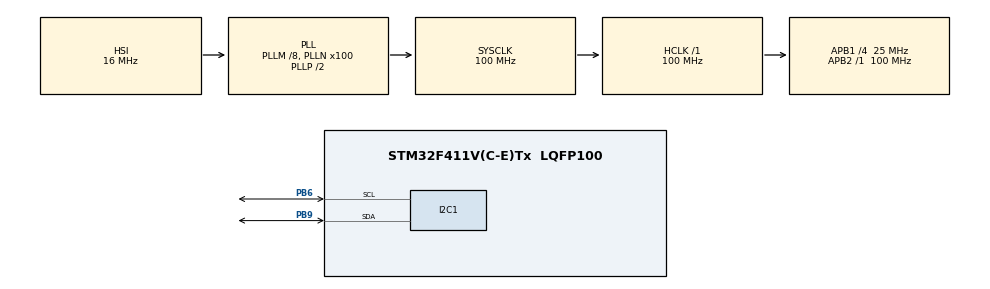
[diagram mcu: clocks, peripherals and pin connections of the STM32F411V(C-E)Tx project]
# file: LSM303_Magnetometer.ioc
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Dma.I2C1_RX.0.Direction=DMA_PERIPH_TO_MEMORY
Dma.I2C1_RX.0.FIFOMode=DMA_FIFOMODE_DISABLE
Dma.I2C1_RX.0.Instance=DMA1_Stream0
Dma.I2C1_RX.0.MemDataAlignment=DMA_MDATAALIGN_BYTE
Dma.I2C1_RX.0.MemInc=DMA_MINC_ENABLE
Dma.I2C1_RX.0.Mode=DMA_CIRCULAR
Dma.I2C1_RX.0.PeriphDataAlignment=DMA_PDATAALIGN_BYTE
Dma.I2C1_RX.0.PeriphInc=DMA_PINC_DISABLE
Dma.I2C1_RX.0.Priority=DMA_PRIORITY_LOW
Dma.I2C1_TX.1.Direction=DMA_MEMORY_TO_PERIPH
Dma.I2C1_TX.1.FIFOMode=DMA_FIFOMODE_DISABLE
Dma.I2C1_TX.1.Instance=DMA1_Stream1
Dma.I2C1_TX.1.MemDataAlignment=DMA_MDATAALIGN_BYTE
Dma.I2C1_TX.1.MemInc=DMA_MINC_ENABLE
Dma.I2C1_TX.1.Mode=DMA_CIRCULAR
Dma.I2C1_TX.1.PeriphDataAlignment=DMA_PDATAALIGN_BYTE
Dma.I2C1_TX.1.PeriphInc=DMA_PINC_DISABLE
Dma.I2C1_TX.1.Priority=DMA_PRIORITY_LOW
Dma.Request0=I2C1_RX
Dma.Request1=I2C1_TX
I2C1.I2C_Mode=I2C_Fast
Mcu.Family=STM32F4
Mcu.Name=STM32F411V(C-E)Tx
Mcu.Package=LQFP100
NVIC.DMA1_Stream0_IRQn=true\:0\:0\:false\:false\:true
NVIC.DMA1_Stream1_IRQn=true\:0\:0\:false\:false\:true
NVIC.PriorityGroup=NVIC_PRIORITYGROUP_4
PB6.Mode=I2C
PB6.Signal=I2C1_SCL
PB9.Mode=I2C
PB9.Signal=I2C1_SDA
ProjectManager.HeapSize=0x200
ProjectManager.StackSize=0x400
ProjectManager.TargetToolchain=SW4STM32
RCC.48MHZClocksFreq_Value=50000000
RCC.AHBFreq_Value=100000000
RCC.APB1CLKDivider=RCC_HCLK_DIV4
RCC.APB1Freq_Value=25000000
RCC.APB1TimFreq_Value=50000000
RCC.APB2Freq_Value=100000000
RCC.APB2TimFreq_Value=100000000
RCC.CortexFreq_Value=100000000
RCC.HCLKFreq_Value=100000000
RCC.HSE_VALUE=25000000
RCC.HSI_VALUE=16000000
RCC.LSE_VALUE=32768
RCC.PLLM=8
RCC.PLLN=100
RCC.SYSCLKFreq_VALUE=100000000
RCC.SYSCLKSource=RCC_SYSCLKSOURCE_PLLCLK
RCC.VCOOutputFreq_Value=200000000
board=LSM303_Magnetometer

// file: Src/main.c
/**
  ******************************************************************************
  * File Name          : main.c
  * Description        : Main program body
  ******************************************************************************
  *
  * COPYRIGHT(c) 2017 STMicroelectronics
  *
  * Redistribution and use in source and binary forms, with or without modification,
  * are permitted provided that the following conditions are met:
  *   1. Redistributions of source code must retain the above copyright notice,
  *      this list of conditions and the following disclaimer.
  *   2. Redistributions in binary form must reproduce the above copyright notice,
  *      this list of conditions and the following disclaimer in the documentation
  *      and/or other materials provided with the distribution.
  *   3. Neither the name of STMicroelectronics nor the names of its contributors
  *      may be used to endorse or promote products derived from this software
  *      without specific prior written permission.
  *
  * THIS SOFTWARE IS PROVIDED BY THE COPYRIGHT HOLDERS AND CONTRIBUTORS "AS IS"
  * AND ANY EXPRESS OR IMPLIED WARRANTIES, INCLUDING, BUT NOT LIMITED TO, THE
  * IMPLIED WARRANTIES OF MERCHANTABILITY AND FITNESS FOR A PARTICULAR PURPOSE ARE
  * DISCLAIMED. IN NO EVENT SHALL THE COPYRIGHT HOLDER OR CONTRIBUTORS BE LIABLE
  * FOR ANY DIRECT, INDIRECT, INCIDENTAL, SPECIAL, EXEMPLARY, OR CONSEQUENTIAL
  * DAMAGES (INCLUDING, BUT NOT LIMITED TO, PROCUREMENT OF SUBSTITUTE GOODS OR
  * SERVICES; LOSS OF USE, DATA, OR PROFITS; OR BUSINESS INTERRUPTION) HOWEVER
  * CAUSED AND ON ANY THEORY OF LIABILITY, WHETHER IN CONTRACT, STRICT LIABILITY,
  * OR TORT (INCLUDING NEGLIGENCE OR OTHERWISE) ARISING IN ANY WAY OUT OF THE USE
  * OF THIS SOFTWARE, EVEN IF ADVISED OF THE POSSIBILITY OF SUCH DAMAGE.
  *
  ******************************************************************************
  */
#include "main.h"
#include "stm32f4xx_hal.h"

/* USER CODE BEGIN Includes */
#include <limits.h>
#include <math.h>
/* USER CODE END Includes */

I2C_HandleTypeDef hi2c1;
DMA_HandleTypeDef hdma_i2c1_rx;
DMA_HandleTypeDef hdma_i2c1_tx;

/* USER CODE BEGIN PV */
/* Private variables ---------------------------------------------------------*/

//MAGNETOMETER ADDRESS
#define LSM303_MAG_ADDRESS (0x1E << 1) //Shift to left because LSB is either 0 or 1, depend on Read or Write operation; HAL drivers set this bit by itself

//CRA_REG_M = [TEMP_EN][0][0][DO2][DO1][DO0][0][0]
#define LSM303_MAG_CRA_REG_M 0x00
#define LSM303_MAG_TEMP_EN 0x80 //Temperature enable
#define LSM303_MAG_0_7_5_HZ 0x00 //DO2-DO0 = 000
#define LSM303_MAG_1_5_HZ 0x04 //DO2-DO0 = 001
#define LSM303_MAG_3_0_HZ 0x08
#define LSM303_MAG_7_5_HZ 0x0C
#define LSM303_MAG_15_HZ 0x10
#define LSM303_MAG_75_HZ 0x18
#define LSM303_MAG_220_HZ 0x1C

//CRB_REG_M = [GN2][GN1][GN0][0][0][0][0][0]
#define LSM303_MAG_CRB_REG_M 0x01
///////////////////////////////////////
#define LSM303_MAG_GAIN_1_3 0x20
#define LSM303_MAG_XY_GAIN_1_3 1100
#define LSM303_MAG_Z_GAIN_1_3 980
///////////////////////////////////////
#define LSM303_MAG_GAIN_1_9 0x40
///////////////////////////////////////
#define LSM303_MAG_GAIN_2_5 0x60
///////////////////////////////////////
#define LSM303_MAG_GAIN_4_0 0x80
///////////////////////////////////////
#define LSM303_MAG_GAIN_4_7 0xA0
///////////////////////////////////////
#define LSM303_MAG_GAIN_5_6 0xC0
///////////////////////////////////////
#define LSM303_MAG_GAIN_8_1 0xD0
#define LSM303_MAG_XY_GAIN_8_1 230
#define LSM303_MAG_Z_GAIN_8_1 205
///////////////////////////////////////

//MR_REG_M = [0][0][0][0][0][0][MD1][MD0]
#define LSM303_MAG_MR_REG_M 0x02
#define LSM303_MAG_CONT_CONV 0x00 //Continuous-conversion mode
#define LSM303_MAG_SINGLE_CONV 0x01
#define LSM303_MAG_SLEEP_MODE1 0x02 //Same as mode2
#define LSM303_MAG_SLEEP_MODE2 0x03 //Same as mode1

//OUT REGISTERS
#define LSM303_MAG_OUT_X_H_M 0x03
#define LSM303_MAG_OUT_X_L_M 0x04
#define LSM303_MAG_OUT_Z_H_M 0x05
#define LSM303_MAG_OUT_Z_L_M 0x06
#define LSM303_MAG_OUT_Y_H_M 0x07
#define LSM303_MAG_OUT_Y_L_M 0x08

#define LSM303_MAG_OUT_XYZ_MULTIREAD (LSM303_MAG_OUT_X_H_M | 0x80)

//SR_REG_M = [--][--][--][--][--][--][LOCK][DRDY]
#define LSM303_MAG_SR_REG_M 0x09
#define LSM303_MAG_LOCK 0x02
#define LSM303_MAG_DATA_READY 0x01

//TEMPERATURE; 12 bits resolution
#define LSM303_MAG_TEMP_OUT_H_M 0x31
#define LSM303_MAG_TEMP_OUT_L_M 0x32
//OTHER SETTINGS
#define LSM303_MAG_RESOLUTION 12

#define LSM303_ACC_XYZ_ENABLE 0x07
#define LSM303_ACC_CTRL_REG1_A 0x20
#define LSM303_ACC_ADDRESS (0x19 << 1)

#define GAUSS_TO_MICROTESLA 100

uint8_t Data[6];
int16_t Axis[3];
float Axis_Gauss[3];
float X_max = 0;
float X_min = 0;

/* USER CODE END PV */

void SystemClock_Config(void);
void Error_Handler(void);
static void MX_GPIO_Init(void);
static void MX_DMA_Init(void);
static void MX_I2C1_Init(void);

/* USER CODE BEGIN PFP */
/* Private function prototypes -----------------------------------------------*/

/* USER CODE END PFP */

int main(void)
{

  /* USER CODE BEGIN 1 */
	uint8_t settings;
  /* USER CODE END 1 */

  /* MCU Configuration----------------------------------------------------------*/

  /* Reset of all peripherals, Initializes the Flash interface and the Systick. */
  HAL_Init();

  /* Configure the system clock */
  SystemClock_Config();

  /* Initialize all configured peripherals */
  MX_GPIO_Init();
  MX_DMA_Init();
  MX_I2C1_Init();

  /* USER CODE BEGIN 2 */
	settings = LSM303_MAG_CONT_CONV;
	HAL_I2C_Mem_Write(&hi2c1, LSM303_MAG_ADDRESS, LSM303_MAG_MR_REG_M, 1, &settings, 1, 100);

	settings = LSM303_MAG_7_5_HZ;
	HAL_I2C_Mem_Write(&hi2c1, LSM303_MAG_ADDRESS, LSM303_MAG_CRA_REG_M, 1, &settings, 1, 100);

	settings = LSM303_MAG_GAIN_1_3;
	HAL_I2C_Mem_Write(&hi2c1, LSM303_MAG_ADDRESS, LSM303_MAG_CRB_REG_M, 1, &settings, 1, 100);

//	settings = LSM303_ACC_XYZ_ENABLE;
//	HAL_I2C_Mem_Write(&hi2c1, LSM303_ACC_ADDRESS, LSM303_ACC_CTRL_REG1_A, 1, &settings, 1, 100);

  /* USER CODE END 2 */

  /* Infinite loop */
  /* USER CODE BEGIN WHILE */
	while (1) {
		HAL_I2C_Mem_Read_DMA(&hi2c1, LSM303_MAG_ADDRESS, LSM303_MAG_OUT_X_H_M, 1, Data, 6);
		Axis[0] = (int16_t)(Data[1] | ((int16_t)Data[0] << 8)); //X
		Axis[1] = (int16_t)(Data[5] | ((int16_t)Data[4] << 8)); //Y
		Axis[2] = (int16_t)(Data[3] | ((int16_t)Data[2] << 8)); //Z

//		temp[0] = ((float)Axis[0] * LSM303_MAG_RESOLUTION) / (float)INT16_MAX;
//		temp[1] = ((float)Axis[1] * LSM303_MAG_RESOLUTION) / (float)INT16_MAX;
//		temp[2] = ((float)Axis[2] * LSM303_MAG_RESOLUTION) / (float)INT16_MAX;

//		Axis_Gauss[0] = (temp[0] / LSM303_MAG_XY_GAIN_1_3)*100;
//		Axis_Gauss[1] = (temp[1] / LSM303_MAG_XY_GAIN_1_3)*100;
//		Axis_Gauss[2] = (temp[2] / LSM303_MAG_Z_GAIN_1_3)*100;

		Axis_Gauss[0] = (float)Axis[0] / LSM303_MAG_XY_GAIN_1_3*GAUSS_TO_MICROTESLA;
		Axis_Gauss[1] = (float)Axis[1] / LSM303_MAG_XY_GAIN_1_3*GAUSS_TO_MICROTESLA;
		Axis_Gauss[2] = (float)Axis[2] / LSM303_MAG_Z_GAIN_1_3*GAUSS_TO_MICROTESLA;

//		if (Axis_Gauss[0] > X_max)
//			X_max = Axis_Gauss[0];
//		else if (Axis_Gauss[0] < X_min)
//			X_min = Axis_Gauss[0];

  /* USER CODE END WHILE */

	}

}

/** System Clock Configuration
*/
void SystemClock_Config(void)
{

  RCC_OscInitTypeDef RCC_OscInitStruct;
  RCC_ClkInitTypeDef RCC_ClkInitStruct;

    /**Configure the main internal regulator output voltage
    */
  __HAL_RCC_PWR_CLK_ENABLE();

  __HAL_PWR_VOLTAGESCALING_CONFIG(PWR_REGULATOR_VOLTAGE_SCALE1);

    /**Initializes the CPU, AHB and APB busses clocks
    */
  RCC_OscInitStruct.OscillatorType = RCC_OSCILLATORTYPE_HSI;
  RCC_OscInitStruct.HSIState = RCC_HSI_ON;
  RCC_OscInitStruct.HSICalibrationValue = 16;
  RCC_OscInitStruct.PLL.PLLState = RCC_PLL_ON;
  RCC_OscInitStruct.PLL.PLLSource = RCC_PLLSOURCE_HSI;
  RCC_OscInitStruct.PLL.PLLM = 8;
  RCC_OscInitStruct.PLL.PLLN = 100;
  RCC_OscInitStruct.PLL.PLLP = RCC_PLLP_DIV2;
  RCC_OscInitStruct.PLL.PLLQ = 4;
  if (HAL_RCC_OscConfig(&RCC_OscInitStruct) != HAL_OK)
  {
    Error_Handler();
  }

    /**Initializes the CPU, AHB and APB busses clocks
    */
  RCC_ClkInitStruct.ClockType = RCC_CLOCKTYPE_HCLK|RCC_CLOCKTYPE_SYSCLK
                              |RCC_CLOCKTYPE_PCLK1|RCC_CLOCKTYPE_PCLK2;
  RCC_ClkInitStruct.SYSCLKSource = RCC_SYSCLKSOURCE_PLLCLK;
  RCC_ClkInitStruct.AHBCLKDivider = RCC_SYSCLK_DIV1;
  RCC_ClkInitStruct.APB1CLKDivider = RCC_HCLK_DIV4;
  RCC_ClkInitStruct.APB2CLKDivider = RCC_HCLK_DIV1;

  if (HAL_RCC_ClockConfig(&RCC_ClkInitStruct, FLASH_LATENCY_3) != HAL_OK)
  {
    Error_Handler();
  }

    /**Configure the Systick interrupt time
    */
  HAL_SYSTICK_Config(HAL_RCC_GetHCLKFreq()/1000);

    /**Configure the Systick
    */
  HAL_SYSTICK_CLKSourceConfig(SYSTICK_CLKSOURCE_HCLK);

  /* SysTick_IRQn interrupt configuration */
  HAL_NVIC_SetPriority(SysTick_IRQn, 0, 0);
}

/* I2C1 init function */
static void MX_I2C1_Init(void)
{

  hi2c1.Instance = I2C1;
  hi2c1.Init.ClockSpeed = 400000;
  hi2c1.Init.DutyCycle = I2C_DUTYCYCLE_2;
  hi2c1.Init.OwnAddress1 = 0;
  hi2c1.Init.AddressingMode = I2C_ADDRESSINGMODE_7BIT;
  hi2c1.Init.DualAddressMode = I2C_DUALADDRESS_DISABLE;
  hi2c1.Init.OwnAddress2 = 0;
  hi2c1.Init.GeneralCallMode = I2C_GENERALCALL_DISABLE;
  hi2c1.Init.NoStretchMode = I2C_NOSTRETCH_DISABLE;
  if (HAL_I2C_Init(&hi2c1) != HAL_OK)
  {
    Error_Handler();
  }

}

static void MX_DMA_Init(void)
{
  /* DMA controller clock enable */
  __HAL_RCC_DMA1_CLK_ENABLE();

  /* DMA interrupt init */
  /* DMA1_Stream0_IRQn interrupt configuration */
  HAL_NVIC_SetPriority(DMA1_Stream0_IRQn, 0, 0);
  HAL_NVIC_EnableIRQ(DMA1_Stream0_IRQn);
  /* DMA1_Stream1_IRQn interrupt configuration */
  HAL_NVIC_SetPriority(DMA1_Stream1_IRQn, 0, 0);
  HAL_NVIC_EnableIRQ(DMA1_Stream1_IRQn);

}

/** Pinout Configuration
*/
static void MX_GPIO_Init(void)
{

  /* GPIO Ports Clock Enable */
  __HAL_RCC_GPIOB_CLK_ENABLE();

}

void Error_Handler(void)
{
	while (1) {
	}
}

/************************ (C) COPYRIGHT STMicroelectronics *****END OF FILE****/
